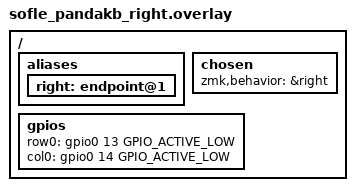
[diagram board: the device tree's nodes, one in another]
/ {
    aliases {
        right: endpoint@1 { };
    };

    chosen {
        zmk,behavior = &right;
    };

    /* Exemple minimal: remplace les pins par les tiens */
    gpios {
        row0 = <&gpio0 13 GPIO_ACTIVE_LOW>;
        col0 = <&gpio0 14 GPIO_ACTIVE_LOW>;
    };
};
